# ESP32-P4 register map
Vendor: ESPRESSIF SYSTEMS (SHANGHAI) CO., LTD.; Series: ESP32 P-Series; File version: 3
CPU: RV32IMAFC r0p0, little endian, no MPU, FPU, 0 interrupt priority bits
Address unit: 32 bits
Registers are 32-bit, read-write, reset 0x0 unless marked. A register's access mark holds for its fields unless they carry their own. Offsets are from the block's base; [hi:lo] are bit positions.

## MIPI_DSI_BRIDGE — MIPI Camera Interface Bridge
Base 0x500A0800
0x00 CLK_EN — dsi bridge clk control register
  [0] CLK_EN — this bit configures force_on of dsi_bridge register clock gate
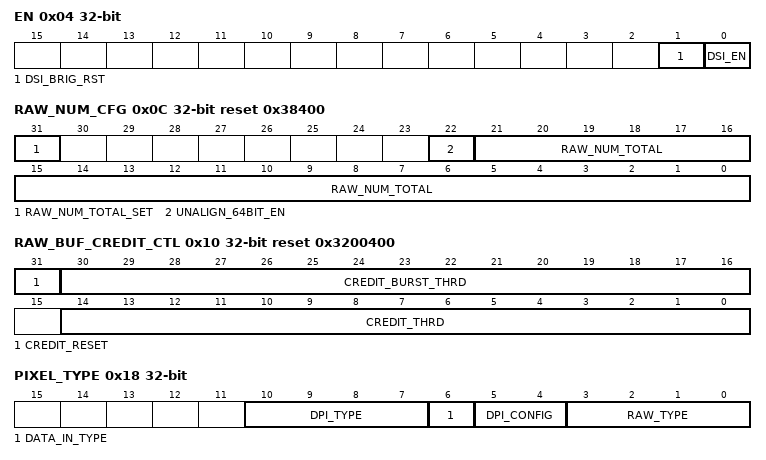
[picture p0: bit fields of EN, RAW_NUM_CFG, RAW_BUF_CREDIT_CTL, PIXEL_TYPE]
0x04 EN — dsi bridge en register
  [1] DSI_BRIG_RST — Configures software reset of dsi_bridge. 0: release reset, 1: reset
  [0] DSI_EN — this bit configures module enable of dsi_bridge. 0: disable, 1: enable
0x08 DMA_REQ_CFG reset 0x80 — dsi bridge dma burst len register
  [11:0] DMA_BURST_LEN — this field configures the num of 64-bit in one dma burst transfer, valid only when dsi_bridge as flow controller
0x0C RAW_NUM_CFG access per field reset 0x38400 — dsi bridge raw number control register
  [31] RAW_NUM_TOTAL_SET wo — this bit configures enable of reload reg_raw_num_total to internal cnt. 0: disable, 1: enable. valid only when dsi_bridge as flow controller
  [22] UNALIGN_64BIT_EN rw — this field configures whether the total pix bits is a multiple of 64bits. 0: align to 64-bit, 1: unalign to 64-bit
  [21:0] RAW_NUM_TOTAL rw — this field configures number of total pix bits/64
0x10 RAW_BUF_CREDIT_CTL reset 0x3200400 — dsi bridge credit register
  [31] CREDIT_RESET — this bit configures internal credit cnt clear, 0: non, 1: reset. valid only when dsi_bridge as flow controller
  [30:16] CREDIT_BURST_THRD — this field configures the threshold whether dsi_bridge fifo can receive one more dma burst, valid only when dsi_bridge as flow controller
  [14:0] CREDIT_THRD — this field configures the threshold whether dsi_bridge fifo can receive one more 64-bit, valid only when dsi_bridge as flow controller
0x14 FIFO_FLOW_STATUS ro — dsi bridge raw buffer depth register
  [13:0] RAW_BUF_DEPTH — this field configures the depth of dsi_bridge fifo depth
0x18 PIXEL_TYPE — dsi bridge dpi type control register
  [10:7] DPI_TYPE — this field configures the dpi pixel type. 0: rgb888, 1:rgb666, 2:rgb565
  [6] DATA_IN_TYPE — input data type, 0: not yuv, 1: yuv
  [5:4] DPI_CONFIG — this field configures the pixel arrange type of dpi interface
  [3:0] RAW_TYPE — this field configures the raw pixel type. 0: rgb888, 1:rgb666, 2:rgb565, 8:yuv444, 9:yuv422, 10:yuv420, 12:gray
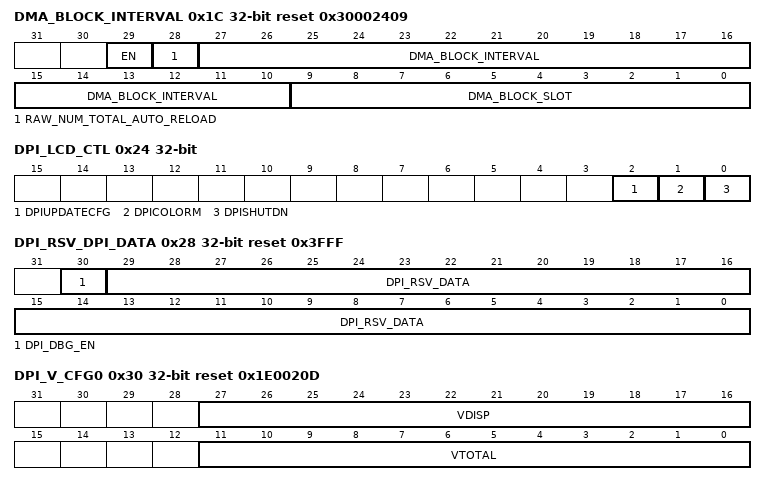
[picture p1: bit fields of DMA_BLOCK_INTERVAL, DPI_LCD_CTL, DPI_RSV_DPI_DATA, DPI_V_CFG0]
0x1C DMA_BLOCK_INTERVAL reset 0x30002409 — dsi bridge dma block interval control register
  [29] EN — this bit configures enable of interval between dma block transfer, 0: disable, 1: enable
  [28] RAW_NUM_TOTAL_AUTO_RELOAD — this bit configures enable of auto reload reg_raw_num_total, 0: disable, 1: enable
  [27:10] DMA_BLOCK_INTERVAL — this field configures the max block_interval_cnt, block_interval_cnt increased by 1 when block_slot_cnt if full
  [9:0] DMA_BLOCK_SLOT — this field configures the max block_slot_cnt
0x20 DMA_REQ_INTERVAL reset 0x1 — dsi bridge dma req interval control register
  [15:0] DMA_REQ_INTERVAL — this field configures the interval between dma req events
0x24 DPI_LCD_CTL — dsi bridge dpi signal control register
  [2] DPIUPDATECFG — this bit configures dpiupdatecfg signal in dpi interface
  [1] DPICOLORM — this bit configures dpicolorm signal in dpi interface
  [0] DPISHUTDN — this bit configures dpishutdn signal in dpi interface
0x28 DPI_RSV_DPI_DATA reset 0x3FFF — dsi bridge dpi reserved data register
  [30] DPI_DBG_EN — Configures data debug feature enable. 0: disable, 1: enable
  [29:0] DPI_RSV_DATA — this field controls the pixel data sent to dsi_host when dsi_bridge fifo underflow
0x30 DPI_V_CFG0 reset 0x1E0020D — dsi bridge dpi v config register 0
  [27:16] VDISP — this field configures the length of valid line (by line) for dpi output
  [11:0] VTOTAL — this field configures the total length of one frame (by line) for dpi output, must meet: reg_vtotal > reg_vdisp+reg_vsync+reg_vbank
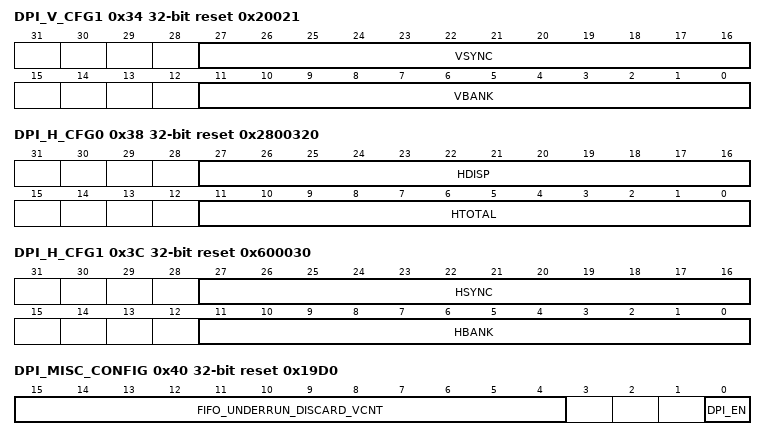
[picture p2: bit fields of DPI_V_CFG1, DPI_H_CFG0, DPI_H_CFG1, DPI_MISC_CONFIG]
0x34 DPI_V_CFG1 reset 0x20021 — dsi bridge dpi v config register 1
  [27:16] VSYNC — this field configures the length of vsync (by line) for dpi output
  [11:0] VBANK — this field configures the length between vsync and valid line (by line) for dpi output
0x38 DPI_H_CFG0 reset 0x2800320 — dsi bridge dpi h config register 0
  [27:16] HDISP — this field configures the length of valid pixel data (by pixel num) for dpi output
  [11:0] HTOTAL — this field configures the total length of one line (by pixel num) for dpi output, must meet: reg_htotal > reg_hdisp+reg_hsync+reg_hbank
0x3C DPI_H_CFG1 reset 0x600030 — dsi bridge dpi h config register 1
  [27:16] HSYNC — this field configures the length of hsync (by pixel num) for dpi output
  [11:0] HBANK — this field configures the length between hsync and pixel data valid (by pixel num) for dpi output
0x40 DPI_MISC_CONFIG reset 0x19D0 — dsi_bridge dpi misc config register
  [15:4] FIFO_UNDERRUN_DISCARD_VCNT — this field configures the underrun interrupt musk, when underrun occurs and line cnt is less then this field
  [0] DPI_EN — this bit configures enable of dpi output, 0: disable, 1: enable
0x44 DPI_CONFIG_UPDATE wo — dsi_bridge dpi config update register
  [0] DPI_CONFIG_UPDATE — write 1 to this bit to update dpi config register MIPI_DSI_BRG_DPI_*
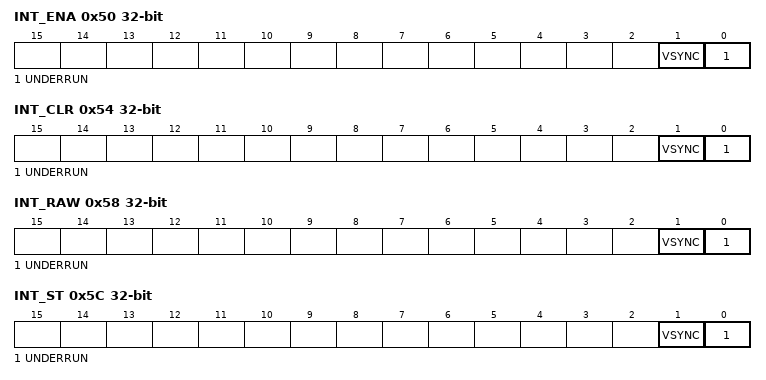
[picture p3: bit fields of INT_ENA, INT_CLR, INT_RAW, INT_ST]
0x50 INT_ENA — dsi_bridge interrupt enable register
  [1] VSYNC — write 1 to enables dpi_vsync_int_st field of MIPI_DSI_BRG_INT_ST_REG controlled by dpi_vsync interrupt signal
  [0] UNDERRUN — write 1 to enables dpi_underrun_int_st field of MIPI_DSI_BRG_INT_ST_REG controlled by dpi_underrun interrupt signal
0x54 INT_CLR wo — dsi_bridge interrupt clear register
  [1] VSYNC write-1-clears — write 1 to this bit to clear dpi_vsync_int_raw field of MIPI_DSI_BRG_INT_RAW_REG
  [0] UNDERRUN write-1-clears — write 1 to this bit to clear dpi_underrun_int_raw field of MIPI_DSI_BRG_INT_RAW_REG
0x58 INT_RAW — dsi_bridge raw interrupt register
  [1] VSYNC — the raw interrupt status of dpi_vsync
  [0] UNDERRUN — the raw interrupt status of dpi_underrun
0x5C INT_ST ro — dsi_bridge masked interrupt register
  [1] VSYNC — the masked interrupt status of dpi_vsync
  [0] UNDERRUN — the masked interrupt status of dpi_underrun
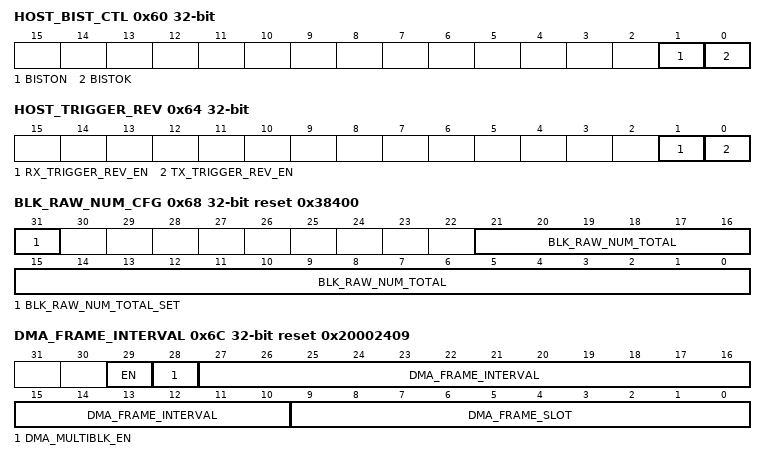
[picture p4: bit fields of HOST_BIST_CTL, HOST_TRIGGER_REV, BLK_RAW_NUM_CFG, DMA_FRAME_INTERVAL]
0x60 HOST_BIST_CTL access per field — dsi_bridge host bist control register
  [1] BISTON rw, [0] BISTOK ro
0x64 HOST_TRIGGER_REV — dsi_bridge host trigger reverse control register
  [1] RX_TRIGGER_REV_EN — rx_trigger reverse. 0: disable, 1: enable
  [0] TX_TRIGGER_REV_EN — tx_trigger reverse. 0: disable, 1: enable
0x68 BLK_RAW_NUM_CFG access per field reset 0x38400 — dsi_bridge block raw number control register
  [31] BLK_RAW_NUM_TOTAL_SET wo — write 1 to reload reg_blk_raw_num_total to internal cnt
  [21:0] BLK_RAW_NUM_TOTAL rw — this field configures number of total block pix bits/64
0x6C DMA_FRAME_INTERVAL reset 0x20002409 — dsi_bridge dam frame interval control register
  [29] EN — this bit configures enable interval between frame transfer, 0: disable, 1: enable
  [28] DMA_MULTIBLK_EN — this bit configures enable multi-blk transfer, 0: disable, 1: enable
  [27:10] DMA_FRAME_INTERVAL — this field configures the max frame_interval_cnt, frame_interval_cnt increased by 1 when frame_slot_cnt if full
  [9:0] DMA_FRAME_SLOT — this field configures the max frame_slot_cnt
0x70 MEM_AUX_CTRL reset 0x1320 — dsi_bridge mem aux control register
  [13:0] DSI_MEM_AUX_CTRL — this field configures dsi_bridge fifo memory aux ctrl
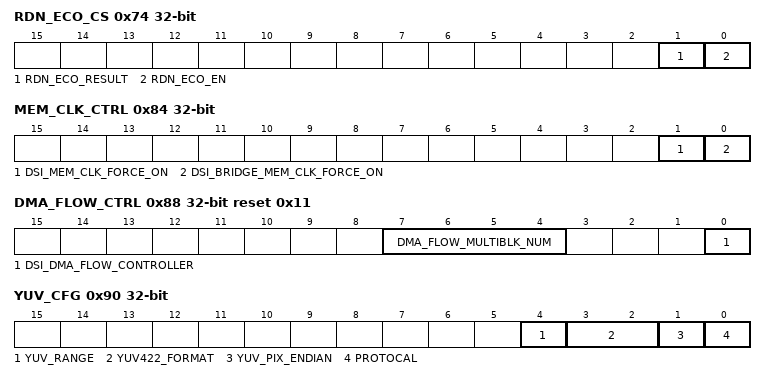
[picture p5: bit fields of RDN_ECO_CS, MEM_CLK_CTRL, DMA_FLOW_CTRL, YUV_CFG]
0x74 RDN_ECO_CS access per field — dsi_bridge rdn eco cs register
  [1] RDN_ECO_RESULT ro, [0] RDN_ECO_EN rw
0x78 RDN_ECO_LOW — dsi_bridge rdn eco all low register
0x7C RDN_ECO_HIGH reset 0xFFFFFFFF — dsi_bridge rdn eco all high register
0x80 HOST_CTRL reset 0x1 — dsi_bridge host control register
  [0] DSI_CFG_REF_CLK_EN — this bit configures the clk enable refclk and cfg_clk of dsi_host. 0: disable, 1: enable
0x84 MEM_CLK_CTRL — dsi_bridge mem force on control register
  [1] DSI_MEM_CLK_FORCE_ON — this bit configures the clock force on of dpi fifo memory. 0: disable, 1: force on
  [0] DSI_BRIDGE_MEM_CLK_FORCE_ON — this bit configures the clock force on of dsi_bridge fifo memory. 0: disable, 1: force on
0x88 DMA_FLOW_CTRL reset 0x11 — dsi_bridge dma flow controller register
  [7:4] DMA_FLOW_MULTIBLK_NUM — this field configures the num of blocks when multi-blk is enable and dmac as flow controller
  [0] DSI_DMA_FLOW_CONTROLLER — this bit configures the flow controller, 0: dmac as flow controller, 1:dsi_bridge as flow controller
0x8C RAW_BUF_ALMOST_EMPTY_THRD reset 0x200 — dsi_bridge buffer empty threshold register
  [10:0] DSI_RAW_BUF_ALMOST_EMPTY_THRD — this field configures the fifo almost empty threshold, is valid only when dmac as flow controller
0x90 YUV_CFG — dsi_bridge yuv format config register
  [4] YUV_RANGE — Configures yuv pixel range, 0: limit range, 1: full range
  [3:2] YUV422_FORMAT — this field configures yuv422 store format, 0: yuyv, 1: yvyu, 2: uyvy, 3: vyuy
  [1] YUV_PIX_ENDIAN — this bit configures yuv pixel endian, 0: y0u0y1v1y2u2y3v3, 1: y3u3y2v2y1u1y0v0
  [0] PROTOCAL — this bit configures yuv protoocl, 0: bt.601, 1: bt.709
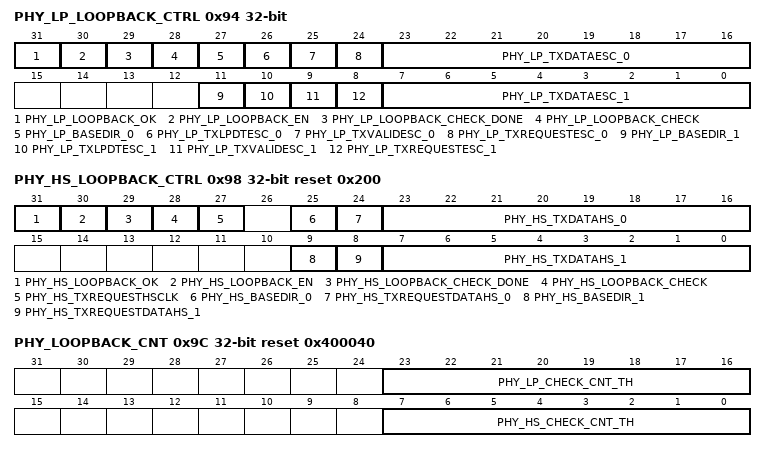
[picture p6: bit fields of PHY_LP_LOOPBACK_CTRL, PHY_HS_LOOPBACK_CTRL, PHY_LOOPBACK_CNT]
0x94 PHY_LP_LOOPBACK_CTRL access per field — dsi phy lp_loopback test ctrl
  [31] PHY_LP_LOOPBACK_OK ro — result of dsi phy lp_loopback test
  [30] PHY_LP_LOOPBACK_EN rw — dsi phy lp_loopback ctrl en
  [29] PHY_LP_LOOPBACK_CHECK_DONE ro — dsi phy lp_loopback test check done
  [28] PHY_LP_LOOPBACK_CHECK wo — dsi phy lp_loopback test start check
  [27] PHY_LP_BASEDIR_0 rw — basedir_0 ctrl when enable dsi phy lp_loopback_test
  [26] PHY_LP_TXLPDTESC_0 rw — txlpdtesc_0 ctrl when enable dsi phy lp_loopback_test
  [25] PHY_LP_TXVALIDESC_0 rw — txvalidesc_0 ctrl when enable dsi phy lp_loopback_test
  [24] PHY_LP_TXREQUESTESC_0 rw — txrequestesc_0 ctrl when enable dsi phy lp_loopback_test
  [23:16] PHY_LP_TXDATAESC_0 rw — txdataesc_0 ctrl when enable dsi phy lp_loopback_test
  [11] PHY_LP_BASEDIR_1 rw — basedir_1 ctrl when enable dsi phy lp_loopback_test
  [10] PHY_LP_TXLPDTESC_1 rw — txlpdtesc_1 ctrl when enable dsi phy lp_loopback_test
  [9] PHY_LP_TXVALIDESC_1 rw — txvalidesc_1 ctrl when enable dsi phy lp_loopback_test
  [8] PHY_LP_TXREQUESTESC_1 rw — txrequestesc_1 ctrl when enable dsi phy lp_loopback_test
  [7:0] PHY_LP_TXDATAESC_1 rw — txdataesc_1 ctrl when enable dsi phy lp_loopback_test
0x98 PHY_HS_LOOPBACK_CTRL access per field reset 0x200 — dsi phy hp_loopback test ctrl
  [31] PHY_HS_LOOPBACK_OK ro — result of dsi phy hs_loopback test
  [30] PHY_HS_LOOPBACK_EN rw — dsi phy hs_loopback ctrl en
  [29] PHY_HS_LOOPBACK_CHECK_DONE ro — dsi phy hs_loopback test check done
  [28] PHY_HS_LOOPBACK_CHECK wo — dsi phy hs_loopback test start check
  [27] PHY_HS_TXREQUESTHSCLK rw — txrequesthsclk when enable dsi phy hs_loopback_test
  [25] PHY_HS_BASEDIR_0 rw — basedir_0 ctrl when enable dsi phy hs_loopback_test
  [24] PHY_HS_TXREQUESTDATAHS_0 rw — txrequestdatahs_0 ctrl when enable dsi phy hs_loopback_test
  [23:16] PHY_HS_TXDATAHS_0 rw — txdatahs_0 ctrl when enable dsi phy hs_loopback_test
  [9] PHY_HS_BASEDIR_1 rw — basedir_1 ctrl when enable dsi phy hs_loopback_test
  [8] PHY_HS_TXREQUESTDATAHS_1 rw — txrequestdatahs_1 ctrl when enable dsi phy hs_loopback_test
  [7:0] PHY_HS_TXDATAHS_1 rw — txdatahs_1 ctrl when enable dsi phy hs_loopback_test
0x9C PHY_LOOPBACK_CNT reset 0x400040 — loopback test cnt
  [23:16] PHY_LP_CHECK_CNT_TH — lp_loopback test check cnt
  [7:0] PHY_HS_CHECK_CNT_TH — hs_loopback test check cnt
0x100 VER_DATE reset 0x20250109 — version control register
  [31:0] VER_DATA — Represents csv version
0x100 DSI_BRG_VER_DATE
  [31:0] VAL
